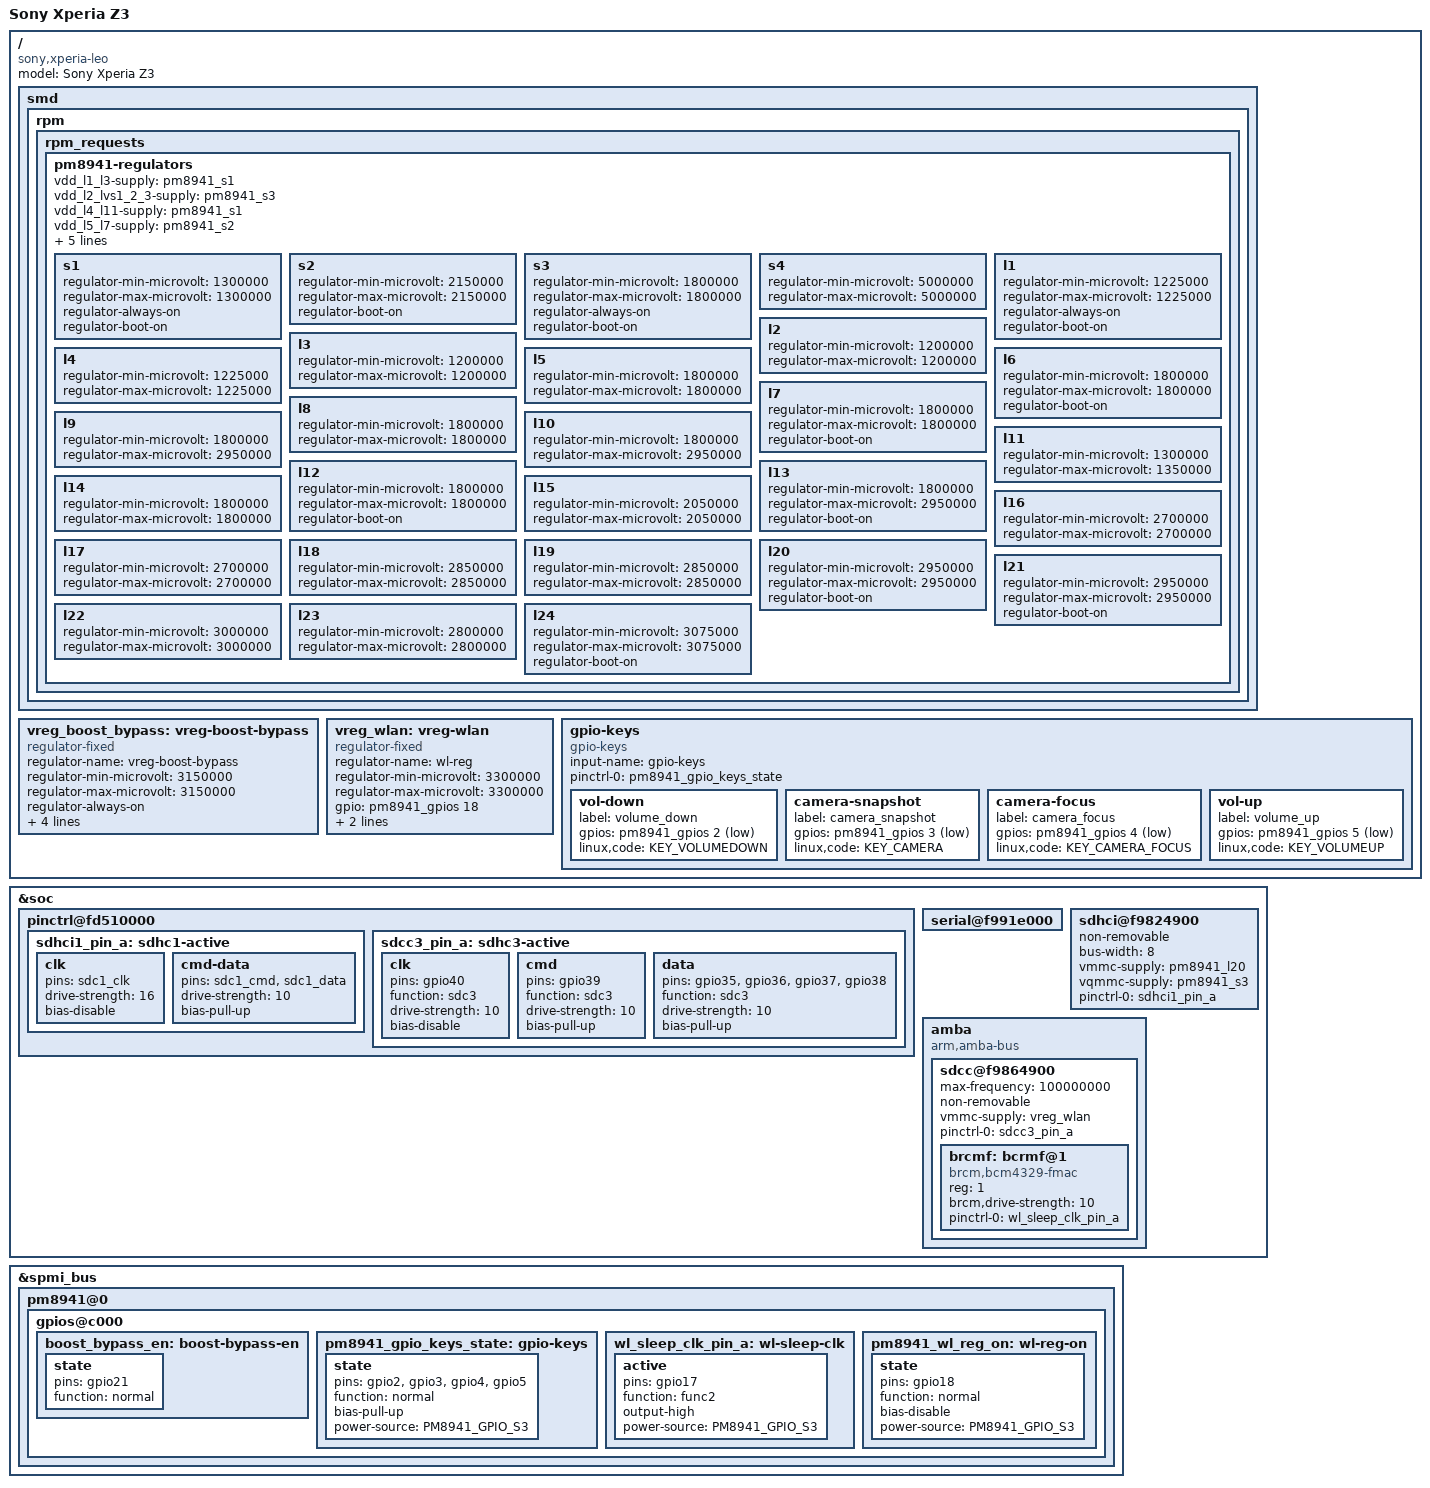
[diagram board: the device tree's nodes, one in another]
#include <dt-bindings/gpio/gpio.h>
#include <dt-bindings/input/input.h>
#include <dt-bindings/pinctrl/qcom,pmic-gpio.h>
#include <dt-bindings/interrupt-controller/arm-gic.h>
#include "qcom-msm8974.dtsi"
#include "qcom-pm8841.dtsi"
#include "qcom-pm8941.dtsi"

/ {
	model = "Sony Xperia Z3";
	compatible = "sony,xperia-leo", "qcom,msm8974";

	smd {
		rpm {
			rpm_requests {
				pm8941-regulators {
					vdd_l1_l3-supply = <&pm8941_s1>;
					vdd_l2_lvs1_2_3-supply = <&pm8941_s3>;
					vdd_l4_l11-supply = <&pm8941_s1>;
					vdd_l5_l7-supply = <&pm8941_s2>;
					vdd_l6_l12_l14_l15-supply = <&pm8941_s2>;
					vdd_l9_l10_l17_l22-supply = <&vreg_boost_bypass>;
					vdd_l13_l20_l23_l24-supply = <&vreg_boost_bypass>;
					vdd_l21-supply = <&vreg_boost_bypass>;
					vin_5vs-supply = <&pm8941_5v>;

					s1 {
						regulator-min-microvolt = <1300000>;
						regulator-max-microvolt = <1300000>;
						regulator-always-on;
						regulator-boot-on;
					};

					s2 {
						regulator-min-microvolt = <2150000>;
						regulator-max-microvolt = <2150000>;
						regulator-boot-on;
					};

					s3 {
						regulator-min-microvolt = <1800000>;
						regulator-max-microvolt = <1800000>;
						regulator-always-on;
						regulator-boot-on;
					};

					s4 {
						regulator-min-microvolt = <5000000>;
						regulator-max-microvolt = <5000000>;
					};

					l1 {
						regulator-min-microvolt = <1225000>;
						regulator-max-microvolt = <1225000>;
						regulator-always-on;
						regulator-boot-on;
					};

					l2 {
						regulator-min-microvolt = <1200000>;
						regulator-max-microvolt = <1200000>;
					};

					l3 {
						regulator-min-microvolt = <1200000>;
						regulator-max-microvolt = <1200000>;
					};

					l4 {
						regulator-min-microvolt = <1225000>;
						regulator-max-microvolt = <1225000>;
					};

					l5 {
						regulator-min-microvolt = <1800000>;
						regulator-max-microvolt = <1800000>;
					};

					l6 {
						regulator-min-microvolt = <1800000>;
						regulator-max-microvolt = <1800000>;
						regulator-boot-on;
					};

					l7 {
						regulator-min-microvolt = <1800000>;
						regulator-max-microvolt = <1800000>;
						regulator-boot-on;
					};

					l8 {
						regulator-min-microvolt = <1800000>;
						regulator-max-microvolt = <1800000>;
					};

					l9 {
						regulator-min-microvolt = <1800000>;
						regulator-max-microvolt = <2950000>;
					};

					l10 {
						regulator-min-microvolt = <1800000>;
						regulator-max-microvolt = <2950000>;
					};

					l11 {
						regulator-min-microvolt = <1300000>;
						regulator-max-microvolt = <1350000>;
					};

					l12 {
						regulator-min-microvolt = <1800000>;
						regulator-max-microvolt = <1800000>;
						regulator-boot-on;
					};

					l13 {
						regulator-min-microvolt = <1800000>;
						regulator-max-microvolt = <2950000>;
						regulator-boot-on;
					};

					l14 {
						regulator-min-microvolt = <1800000>;
						regulator-max-microvolt = <1800000>;
					};

					l15 {
						regulator-min-microvolt = <2050000>;
						regulator-max-microvolt = <2050000>;
					};

					l16 {
						regulator-min-microvolt = <2700000>;
						regulator-max-microvolt = <2700000>;
					};

					l17 {
						regulator-min-microvolt = <2700000>;
						regulator-max-microvolt = <2700000>;
					};

					l18 {
						regulator-min-microvolt = <2850000>;
						regulator-max-microvolt = <2850000>;
					};

					l19 {
						regulator-min-microvolt = <2850000>;
						regulator-max-microvolt = <2850000>;
					};

					l20 {
						regulator-min-microvolt = <2950000>;
						regulator-max-microvolt = <2950000>;
						regulator-boot-on;
					};

					l21 {
						regulator-min-microvolt = <2950000>;
						regulator-max-microvolt = <2950000>;
						regulator-boot-on;
					};

					l22 {
						regulator-min-microvolt = <3000000>;
						regulator-max-microvolt = <3000000>;
					};

					l23 {
						regulator-min-microvolt = <2800000>;
						regulator-max-microvolt = <2800000>;
					};

					l24 {
						regulator-min-microvolt = <3075000>;
						regulator-max-microvolt = <3075000>;
						regulator-boot-on;
					};
				};
			};
		};
	};

	vreg_boost_bypass: vreg-boost-bypass {
		compatible = "regulator-fixed";

		regulator-name = "vreg-boost-bypass";
		regulator-min-microvolt = <3150000>;
		regulator-max-microvolt = <3150000>;

		regulator-always-on;
		regulator-boot-on;

		gpio = <&pm8941_gpios 21 0>;
		enable-active-high;

		pinctrl-names = "default";
		pinctrl-0 = <&boost_bypass_en>;
	};

	vreg_wlan: vreg-wlan {
		compatible = "regulator-fixed";

		regulator-name = "wl-reg";
		regulator-min-microvolt = <3300000>;
		regulator-max-microvolt = <3300000>;

		gpio = <&pm8941_gpios 18 GPIO_ACTIVE_HIGH>;
		enable-active-high;

		pinctrl-names = "default";
		pinctrl-0 = <&pm8941_wl_reg_on>;
	};

	gpio-keys {
		compatible = "gpio-keys";
		input-name = "gpio-keys";

		pinctrl-names = "default";
		pinctrl-0 = <&pm8941_gpio_keys_state>;

		vol-down {
			label = "volume_down";
			gpios = <&pm8941_gpios 2 GPIO_ACTIVE_LOW>;
			linux,code = <KEY_VOLUMEDOWN>;
		};

		camera-snapshot {
			label = "camera_snapshot";
			gpios = <&pm8941_gpios 3 GPIO_ACTIVE_LOW>;
			linux,code = <KEY_CAMERA>;
		};

		camera-focus {
			label = "camera_focus";
			gpios = <&pm8941_gpios 4 GPIO_ACTIVE_LOW>;
			linux,code = <KEY_CAMERA_FOCUS>;
		};

		vol-up {
			label = "volume_up";
			gpios = <&pm8941_gpios 5 GPIO_ACTIVE_LOW>;
			linux,code = <KEY_VOLUMEUP>;
		};
	};
};

&soc {
	pinctrl@fd510000 {
		sdhci1_pin_a: sdhc1-active {
			clk {
				pins = "sdc1_clk";
				drive-strength = <16>;
				bias-disable;
			};

			cmd-data {
				pins = "sdc1_cmd", "sdc1_data";
				drive-strength = <10>;
				bias-pull-up;
			};
		};

		sdcc3_pin_a: sdhc3-active {
			clk {
				pins = "gpio40";
				function = "sdc3";

				drive-strength = <10>;
				bias-disable;
			};

			cmd {
				pins = "gpio39";
				function = "sdc3";

				drive-strength = <10>;
				bias-pull-up;
			};

			data {
				pins = "gpio35", "gpio36", "gpio37", "gpio38";
				function = "sdc3";

				drive-strength = <10>;
				bias-pull-up;
			};
		};
	};

	serial@f991e000 {
		status = "ok";
	};

	sdhci@f9824900 {
		status = "ok";

		non-removable;
		bus-width = <8>;

		vmmc-supply = <&pm8941_l20>;
		vqmmc-supply = <&pm8941_s3>;

		pinctrl-names = "default";
		pinctrl-0 = <&sdhci1_pin_a>;
	};

	amba {
		compatible = "arm,amba-bus";
		#address-cells = <1>;
		#size-cells = <1>;
		ranges;

		sdcc@f9864900 {
			status = "ok";

			#address-cells = <1>;
			#size-cells = <0>;

			max-frequency	= <100000000>;
			non-removable;
			vmmc-supply = <&vreg_wlan>;

			pinctrl-names = "default";
			pinctrl-0 = <&sdcc3_pin_a>;

			brcmf: bcrmf@1 {
				compatible = "brcm,bcm4329-fmac";
				reg = <1>;

				brcm,drive-strength = <10>;

				pinctrl-names = "default";
				pinctrl-0 = <&wl_sleep_clk_pin_a>;
			};
		};
	};
};

&spmi_bus {
	pm8941@0 {
		gpios@c000 {
			boost_bypass_en: boost-bypass-en {
				state {
					pins = "gpio21";
					function = "normal";
				};
			};

			pm8941_gpio_keys_state: gpio-keys {
				state {
					pins = "gpio2", "gpio3", "gpio4", "gpio5";
					function = "normal";
					bias-pull-up;
					power-source = <PM8941_GPIO_S3>;
				};
			};

			wl_sleep_clk_pin_a: wl-sleep-clk {
				active {
					pins = "gpio17";
					function = "func2";

					output-high;
					power-source = <PM8941_GPIO_S3>;
				};
			};

			pm8941_wl_reg_on: wl-reg-on {
				state {
					pins = "gpio18";
					function = "normal";

					bias-disable;
					power-source = <PM8941_GPIO_S3>;
				};
			};
		};
	};
};
